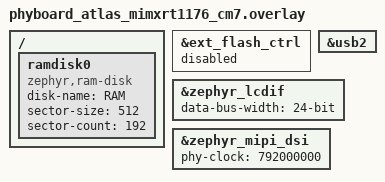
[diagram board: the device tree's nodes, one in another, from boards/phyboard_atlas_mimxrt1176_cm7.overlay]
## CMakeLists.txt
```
#-------------------------------------------------------------------------------
# phyCORE-RT1170
#
# Copyright (c) 2025 PHYTEC
# SPDX-License-Identifier: Apache-2.0

cmake_minimum_required(VERSION 3.13.1)
find_package(Zephyr REQUIRED HINTS $ENV{ZEPHYR_BASE})

project(app LANGUAGES C)

target_sources(app PRIVATE src/main.c)
```

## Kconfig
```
# Copyright (c) 2025 PHYTEC
# SPDX-License-Identifier: Apache-2.0
#
# This file is the application Kconfig entry point. All application Kconfig
# options can be defined here or included via other application Kconfig files.
# You can browse these options using the west targets menuconfig (terminal) or
# guiconfig (GUI).

menu "Zephyr"
source "Kconfig.zephyr"
endmenu

module = APP
module-str = APP
source "subsys/logging/Kconfig.template.log_config"
```

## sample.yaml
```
# This file is provided so that the application can be compiled using Twister,
# the Zephyr testing tool. In this file, multiple combinations can be specified,
# so that you can easily test all of them locally or in CI.
sample:
  description: Example application
  name: example-application
common:
  build_only: true
  integration_platforms:
    - phycore_rt1170/mimxrt1176/cm7
    - phycore_rt1170/mimxrt1176/cm4
tests:
  app.default: {}
  app.debug:
    extra_overlay_confs:
      - debug.conf
      - shell.conf
      - net.conf
```

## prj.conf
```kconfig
# Copyright (c) 2025 PHYTEC
# SPDX-License-Identifier: Apache-2.0
#
# This file contains selected Kconfig options for the application.

CONFIG_BOOT_BANNER=y

CONFIG_BUILD_OUTPUT_META=y

CONFIG_AUDIO=y
CONFIG_AUDIO_CODEC=y
CONFIG_CAN=y
CONFIG_CAN_FD_MODE=y
CONFIG_COUNTER=y
CONFIG_DAC=y
CONFIG_DISPLAY=y
CONFIG_DMA=y
CONFIG_EEPROM=y
CONFIG_I2S=y
CONFIG_INPUT=y
CONFIG_LED=y
CONFIG_NETWORKING=y
CONFIG_RTC=y
CONFIG_SENSOR=y
CONFIG_SPI=y
CONFIG_USB_DEVICE_STACK_NEXT=y
CONFIG_WATCHDOG=y

# Increase minimum timeout window for mcux driver
CONFIG_TASK_WDT_MIN_TIMEOUT=500

# USB Device parameters
CONFIG_SAMPLE_USBD_PID=0xcafe
CONFIG_SAMPLE_USBD_PRODUCT="USBD MSC sample"
CONFIG_USBD_MSC_CLASS=y
CONFIG_USBD_MSC_LUNS_PER_INSTANCE=3
CONFIG_APP_MSC_STORAGE_SDCARD=y

# Raise DMA TCD Queue size, as this is required by the I2S SAI driver
CONFIG_DMA_TCD_QUEUE_SIZE=4

# Additional configuration for networking
CONFIG_NET_IPV4=y
CONFIG_NET_TCP=y
CONFIG_NET_DHCPV4=y
CONFIG_NET_IF_MAX_IPV4_COUNT=2
CONFIG_NET_IF_MAX_IPV6_COUNT=2
CONFIG_NET_BUF_DATA_SIZE=1500
CONFIG_NET_TC_TX_COUNT=1
CONFIG_NET_BUF_TX_COUNT=80
CONFIG_NET_BUF_RX_COUNT=80
CONFIG_NET_PKT_TX_COUNT=80
CONFIG_NET_PKT_RX_COUNT=80
CONFIG_ZVFS_POLL_MAX=9

# Configure LVGL
CONFIG_MCUX_ELCDIF_PXP=y
CONFIG_LV_Z_MEM_POOL_SIZE=58368
CONFIG_LV_Z_POINTER_INPUT=y
CONFIG_LV_USE_LABEL=y
CONFIG_LV_USE_ARC=y
CONFIG_LV_USE_MONKEY=y
CONFIG_LV_COLOR_DEPTH_24=y
```

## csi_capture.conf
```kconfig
CONFIG_APP_CSI_CAPTURE=y
CONFIG_VIDEO=y
CONFIG_VIDEO_BUFFER_POOL_HEAP_SIZE=7373600
CONFIG_MCUX_ELCDIF_PXP=y
CONFIG_MCUX_ELCDIF_PXP_ROTATE_90=y
CONFIG_REQUIRES_FLOAT_PRINTF=y
CONFIG_LOG_MODE_DEFERRED=y
```

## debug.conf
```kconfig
# Copyright (c) 2025 PHYTEC
# SPDX-License-Identifier: Apache-2.0
#
# This is a Kconfig fragment which can be used to enable debug-related options
# in the application. See the README for more details.

# compiler
CONFIG_DEBUG_OPTIMIZATIONS=y

# logging
CONFIG_LOG=y
CONFIG_APP_LOG_LEVEL_DBG=y
CONFIG_USB_DEVICE_LOG_LEVEL_ERR=y
CONFIG_USB_DRIVER_LOG_LEVEL_ERR=y
CONFIG_USB_MASS_STORAGE_LOG_LEVEL_ERR=y
CONFIG_USBD_LOG_LEVEL_WRN=y
CONFIG_USBH_LOG_LEVEL_WRN=y
CONFIG_UDC_DRIVER_LOG_LEVEL_WRN=y

# assert
CONFIG_ASSERT=y
```

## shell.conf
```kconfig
# Copyright (c) 2025 PHYTEC
# SPDX-License-Identifier: Apache-2.0
#
# This is a Kconfig fragment which can be used to enable shell-related options
# in the application. See the README for more details.

CONFIG_SHELL=y
CONFIG_GPIO_SHELL=y
CONFIG_LED_SHELL=y
CONFIG_LV_Z_SHELL=y
CONFIG_I2C_SHELL=y
CONFIG_INPUT_SHELL=y
CONFIG_EEPROM_SHELL=y
CONFIG_SPI_SHELL=y
CONFIG_CAN_SHELL=y
CONFIG_CAN_SHELL_SCRIPTING_FRIENDLY=y
CONFIG_COUNTER_SHELL=y
CONFIG_DAC_SHELL=y
CONFIG_WDT_SHELL=y
CONFIG_SENSOR_SHELL=y
CONFIG_TASK_WDT_SHELL=y
CONFIG_UART_SHELL=y
CONFIG_NET_SHELL=y
CONFIG_NET_ZPERF=y

CONFIG_FILE_SYSTEM=y
CONFIG_FILE_SYSTEM_SHELL=y
CONFIG_USBD_SHELL=y
CONFIG_AUDIO_CODEC_SHELL=y
```

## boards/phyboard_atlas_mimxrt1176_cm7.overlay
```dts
/*
 * Copyright (c) 2025 PHYTEC
 * SPDX-License-Identifier: Apache-2.0
 */

/ {
	ramdisk0 {
		compatible = "zephyr,ram-disk";
		disk-name = "RAM";
		sector-size = <512>;
		sector-count = <192>;
	};
};

&ext_flash_ctrl {
	status = "disabled";
};

/delete-node/ &zephyr_udc0;

zephyr_udc0: &usb2 {
	status = "okay";
};

&zephyr_lcdif {
	data-bus-width = "24-bit";
};

&zephyr_mipi_dsi {
	/* Raise the DSI clock frequency */
	phy-clock = <792000000>;
};
```

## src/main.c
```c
/*
 * Copyright (c) 2025 PHYTEC
 *
 * SPDX-License-Identifier: Apache-2.0
 */

#include <stdio.h>
#include <zephyr/kernel.h>

#include "../common/init/watchdog/watchdog.h"

int main(void) {
	/* Enable Watchdog */
	init_watchdog();
}
```
